# psoc4200l register map
Vendor: Cypress Semiconductor; Series: PSoC4200L; File version: 1.0
CPU: CM0 r0p1, little endian, no MPU, no FPU, 2 interrupt priority bits
Registers are 32-bit, read-write, reset 0x0 unless marked. A register's access mark holds for its fields unless they carry their own. Offsets are from the block's base; [hi:lo] are bit positions.

## TST — Test Subsystem
Base 0x40030000
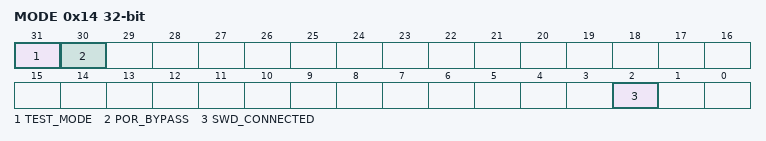
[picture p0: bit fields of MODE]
0x14 MODE — Test Mode Control Register
  [31] TEST_MODE — 0: Normal operation mode 1: Test mode (any test mode) Setting this bit will prevent BootROM from yielding execution to Flash image.
  [30] POR_BYPASS ro — This bit is set during POR bypass mode. When this bit is set, the BootROM will not yield execution to the FLASH image (same function as setting TEST_MODE bit below).
  [2] SWD_CONNECTED ro — 0: SWD not active 1: SWD activated (Line Reset & Connect sequence passed) (Note: this bit replaces TST_CTRL.SWD_CONNECTED and is present in all M0S8 products except TSG4)

## SPCIF — Flash Control Interface
Base 0x40110000
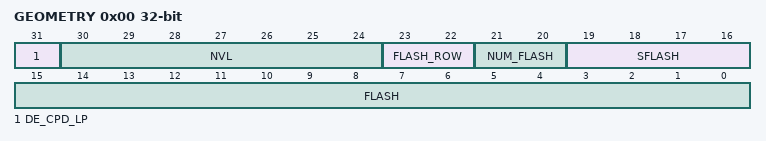
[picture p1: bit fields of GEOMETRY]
0x00 GEOMETRY (reset mask 0x80000000) — Flash/NVL geometry information
  [31] DE_CPD_LP — 0': SRAM busy wait loop has not been copied. '1': Busy wait loop has been written into SRAM.
  [30:24] NVL ro — NVLatch size in Byte multiples (chip dependent): '0': 0 Bytes '1': 1 Byte ... '127': 127 Bytes
  [23:22] FLASH_ROW ro — Page size in 64 Byte multiples (chip dependent): '0': 64 byte '1': 128 byte '2': 192 byte '3': 256 byte The page size is used to detemine the number of Bytes in a page for Flash page based operations (e.g. PGM_PAGE). Note: the field name FLASH_ROW is misleading, as this field specifies the number of Bytes in a page, rather than the number of Bytes in a row. In a single plane flash macro architecture, a page consists of a single row. However, in a multi plane flash macro architecture, a page consists of multiple rows from different planes.
  [21:20] NUM_FLASH ro — Number of flash macros (chip dependent): '0': 1 flash macro '1': 2 flash macros '2': 3 flash macros '3': 4 flash macros
  [19:16] SFLASH ro — Supervisory flash capacity in 256 Byte multiples (chip dependent). If multiple flash macros are present, this field provides the supervisory flash capacity of all flash macros together: '0': 256 Bytes. '1': 2*256 Bytes. ... '15': 16*256 Bytes.
  [15:0] FLASH ro — Regular flash capacity in 256 Byte multiples (chip dependent). If multiple flash macros are present, this field provides the flash capacity of all flash macros together: '0': 256 Bytes. '1': 2*256 Bytes. ... '65535': 65536*256 Bytes.
0x1C NVL_WR_DATA — NVL write data register
  [7:0] DATA — Data to be written to NVLatch array
0x7F0 INTR — SPCIF interrupt request register
  [0] TIMER — Timer counter value reaches '0'. Set to '1', when event is detected. Write INTR field with '1', to clear bit. Write INTR_SET field with '1', to set bit.
0x7F4 INTR_SET — SPCIF interrupt set request register
  [0] TIMER — Write INTR_SET field with '1' to set corresponding INTR field.
0x7F8 INTR_MASK — SPCIF interrupt mask register
  [0] TIMER — Mask for corresponding field in INTR register.
0x7FC INTR_MASKED ro — SPCIF interrupt masked request register
  [0] TIMER — Logical and of corresponding request and mask fields.

## WCO — 32KHz Oscillator
Base 0x40220000
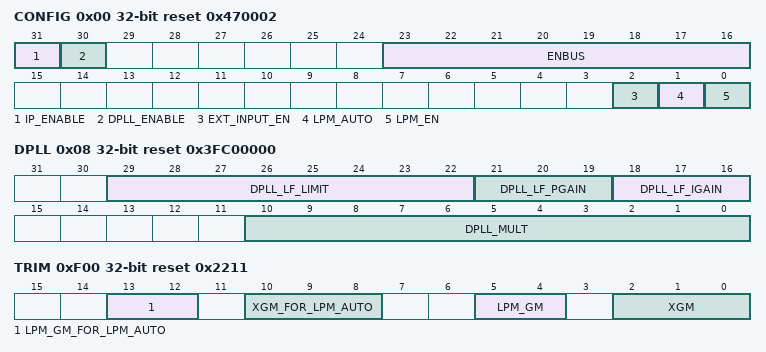
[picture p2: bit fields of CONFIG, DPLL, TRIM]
0x00 CONFIG reset 0x470002 — WCO Configuration Register
  [31] IP_ENABLE — Master enable for IP - disables both WCO and DPLL
  [30] DPLL_ENABLE — Enable DPLL operation. The Oscillator is specified to be stable after 500 ms thus the DPLL should be asserted no sooner than that after IP_ENABLE is set.
  [23:16] ENBUS — Test Mode Control bits enbus[7] - N/A enbus[6] - 1=enable both primary Beta Multipliers enbus[5] - N/A enbus[4] - N/A enbus[3] - Load Resistor Control enbus[2] - Load Resistor Control enbus[1] - Load Resistor Control enbus[0] - Load Resistor Control
  [2] EXT_INPUT_EN — Disables the load resistor and allows external clock input for pad_xin
  [1] LPM_AUTO — Automatically control low power mode (only relevant when LPM_EN=0): 0: Do not enter low power mode (LPM) in DeepSleep 1: Enter low power mode (LPM) in DeepSleep. The logic monitors !act_power_en to determine the device has entered DeepSleep.
  [0] LPM_EN — Force block into Low Power Mode: 0: Do not force low power mode (LPM) on 1: Force low power mode (LPM) on
0x04 STATUS ro — WCO Status Register
  [0] OUT_BLNK_A — Indicates that output has transitioned - This bit is intended for Test Mode Only and is not a reliable indicator.
0x08 DPLL reset 0x3FC00000 — WCO DPLL Register
  [29:22] DPLL_LF_LIMIT — Maximum IMO offset allowed (used to prevent DPLL dynamics from selecting an IMO frequency that the logic cannot support)
  [21:19] DPLL_LF_PGAIN — DPLL Loop Filter Proportionial Gain Setting 0x0 - 0.0625 0x1 - 0.125 0x2 - 0.25 0x3 - 0.5 0x4 - 1.0 0x5 - 2.0 0x6 - 4.0 0x7 - 8.0
  [18:16] DPLL_LF_IGAIN — DPLL Loop Filter Integral Gain Setting 0x0 - 0.0625 0x1 - 0.125 0x2 - 0.25 0x3 - 0.5 0x4 - 1.0 0x5 - 2.0 0x6 - 4.0 0x7 - 8.0
  [10:0] DPLL_MULT — Multiplier to determine IMO frequency in multiples of the WCO frequency Fimo = (DPLL_MULT + 1) * Fwco
0xF00 TRIM reset 0x2211 — WCO Trim Register
  [13:12] LPM_GM_FOR_LPM_AUTO — GM setting for LPM (bandwidth = DC/ms) - Used when WCO.LPM_AUTO=1 and in DeepSleep mode
  [10:8] XGM_FOR_LPM_AUTO — Amplifier GM setting - Used when WCO.LPM_AUTO=1 and in DeepSleep mode 0x0 - 3370 nA 0x1 - 2620 nA 0x2 - 2250 nA 0x3 - 1500 nA 0x4 - 1870 nA 0x5 - 1120 nA 0x6 - 750 nA 0x7 - 0 nA
  [5:4] LPM_GM — GM setting for LPM (bandwidth = DC/ms) - Used when WCO.LPM_AUTO=0 or when LPM_AUTO=1 and not in DeepSleep mode.
  [2:0] XGM — Amplifier GM setting - Used when WCO.LPM_AUTO=0 or when LPM_AUTO=1 and not in DeepSleep mode. 0x0 - 3370 nA 0x1 - 2620 nA 0x2 - 2250 nA 0x3 - 1500 nA 0x4 - 1870 nA 0x5 - 1120 nA 0x6 - 750 nA 0x7 - 0 nA
